# PIC32CZ4010CA90144 device description
Architecture: CORTEX-M7; Family: PIC32C; Series: PIC32CZCA90
Registers are 32-bit, read-write, reset 0x0 unless marked. A register's access mark holds for its fields unless they carry their own. Offsets are from the block's base; [hi:lo] are bit positions; {n}, {i} and the like mark numbered series; 'fields as' and 'values as' point back to an identical list; <NAME> marks a mode.

## HSM — Hardware Security Module
Instances: HSM 0x4F018000
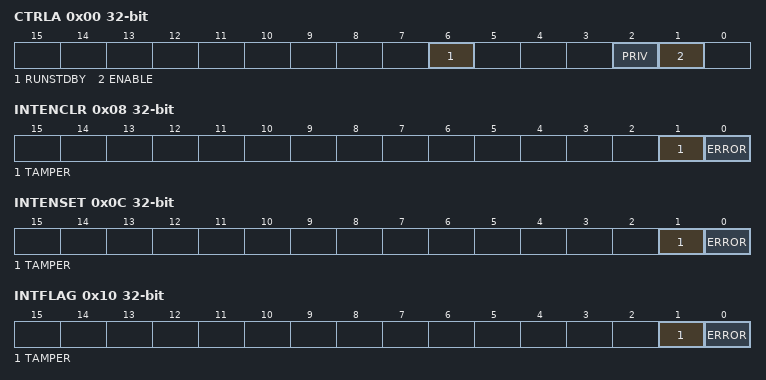
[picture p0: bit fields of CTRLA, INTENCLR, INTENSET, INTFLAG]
0x00 CTRLA — CONTROL REGISTER A
  [6] RUNSTDBY — Run In Standby bit
  [2] PRIV — Privileged Access Only bit
  [1] ENABLE — Clock Enable bit
0x04 CTRLB — CONTROL REGISTER B
  [0] CANCEL — Cancel Command
0x08 INTENCLR (atomic clear) — INTERRUPT ENABLE CLEAR REGISTER
  [1] TAMPER — Tamper Interrupt Enable
  [0] ERROR — Error Interrupt Enable
0x0C INTENSET (atomic set) — INTERRUPT ENABLE SET
  fields as INTENCLR
0x10 INTFLAG (atomic clear) — INTERRUPT FLAG
  [1] TAMPER — Tamper Interrupt Flag
  [0] ERROR — Error Interrupt Flag
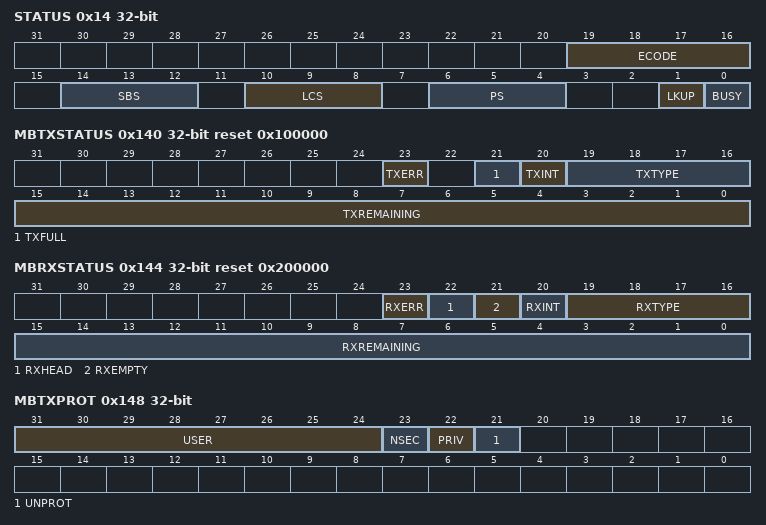
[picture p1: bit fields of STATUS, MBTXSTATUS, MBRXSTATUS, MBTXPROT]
0x14 STATUS
  [19:16] ECODE — ERROR CODE
  [14:12] SBS — SECURE BOOT STATE
  [10:8] LCS — LIFECYCLE STATE
  [6:4] PS — PROCESSING STATE
  [1] LKUP — HSM CPU LOCKUP
  [0] BUSY — HSM CPU BUSY
{0x100+4i} MBFIFO[{i}] (i=0..15) — MAILBOX FIFO
0x140 MBTXSTATUS reset 0x100000 — MAILBOX TRANSMIT STATUS
  [23] TXERR — TRANSMIT ERROR
  [21] TXFULL — TRANSMIT FIFO FULL
  [20] TXINT — TRANSMIT FIFO INTERRUPT FLAG
  [19:16] TXTYPE — TRANSMIT MESSAGE HEADER TYPE
  [15:0] TXREMAINING — TRANSMIT BYTES REMAINING
0x144 MBRXSTATUS reset 0x200000 — MAILBOX RECEIVE STATUS
  [23] RXERR — RECEIVE ERROR
  [22] RXHEAD — Receive Header Next Word bit
  [21] RXEMPTY — RECEIVE FIFO FULL
  [20] RXINT — RECEIVE FIFO INTERRUPT FLAG
  [19:16] RXTYPE — RECEIVE MESSAGE HEADER TYPE
  [15:0] RXREMAINING — RECEIVE BYTES REMAINING
0x148 MBTXPROT — MAILBOX TX PROTECTION
  [31:24] USER — USER SIDEBAND
  [23] NSEC — MAILBOX MESSAGE NON-SECURE ACCESS
  [22] PRIV — MAILBOX MESSAGE PRIVILEDGED ACCESS
  [21] UNPROT — MAILBOX UNPROTECTED
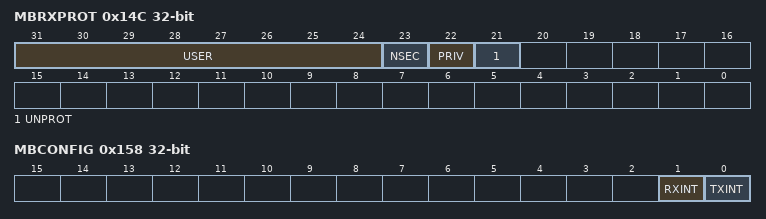
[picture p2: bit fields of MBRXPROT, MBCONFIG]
0x14C MBRXPROT — MAILBOX RX PROTECTION
  fields as MBTXPROT
0x150 MBTXHEAD — MAILBOX TRANSMIT HEADER
  [31:0] TXHEAD — MAILBOX TRANSMIT HEADER REGISTER
0x154 MBRXHEAD — MAILBOX RECEIVE HEADER
  [31:0] RXHEAD — MAILBOX RECEIVE HEADER REGISTER
0x158 MBCONFIG — MAILBOX CONFIGURATION
  [1] RXINT — MAILBOX RECEIVE INTERRUPT ENABLE
  [0] TXINT — MAILBOX TRANSMIT INTERRUPT ENABLE

## ITM — Instrumentation Trace Macrocell
Instances: ITM 0xE0041000
{0x0+4i} PORT[{i}] (i=0..31) wo reset not defined — ITM Stimulus Port Registers
  [7:0] PORT <BYTE>, [15:0] PORT <HWORD>, [31:0] PORT <WORD>
0xE00 TER reset not defined — ITM Trace Enable Register
0xE40 TPR reset not defined — ITM Trace Privilege Register
  [3:0] PRIVMASK
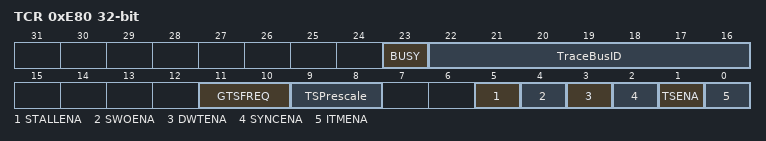
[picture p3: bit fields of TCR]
0xE80 TCR reset not defined — ITM Trace Control Register
  [23] BUSY, [22:16] TraceBusID, [11:10] GTSFREQ, [9:8] TSPrescale, [5] STALLENA, [4] SWOENA, [3] DWTENA, [2] SYNCENA, [1] TSENA, [0] ITMENA
0xEF8 IWR wo reset not defined — ITM Integration Write Register
  [0] ATVALIDM
0xEFC IRR ro reset not defined — ITM Integration Read Register
  [0] ATREADYM

## MCLK — Main Clock
Instances: MCLK 0x44052000
0x00 INTENCLR (atomic clear) — Interrupt Enable Clear
  [0] CKRDY — Clock Ready Interrupt Enable
0x04 INTENSET (atomic set) — Interrupt Enable Set
  [0] CKRDY — Clock Ready Interrupt Enable
0x08 INTFLAG reset 0x1 (atomic clear) — Interrupt Flag Status and Clear
  [0] CKRDY — Clock Ready
{0xC+4i} CLKDIV[{i}] (i=0..1) — Clock Divider Control
  [7:0] DIV — Clock Domain Division Factor
    1=Divide by 1; 2=Divide by 2; 4=Divide by 4; 8=Divide by 8; 16=Divide by 16; 32=Divide by 32; 64=Divide by 64; 128=Divide by 128
{0x3C+4i} CLKMSK[{i}] (i=0..8) — Peripheral Clock Enable Mask
  [31:0] MASK

## MCRAMC — Multi-Channel RAM Controller
Instances: MCRAMC 0x44822000
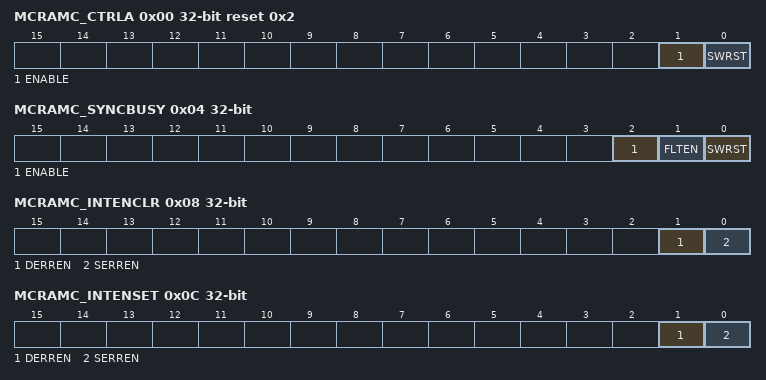
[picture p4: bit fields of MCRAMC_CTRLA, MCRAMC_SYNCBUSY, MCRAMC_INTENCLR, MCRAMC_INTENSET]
0x00 MCRAMC_CTRLA reset 0x2 — Control Enable A Register
  [1] ENABLE — ECC Decoder Enable
    0=ECC decoding is disabled; 1=ECC decoding is enabled
  [0] SWRST — Software Reset
    0=No effect; 1=Reset the MCRAMC. A software-triggered hardware reset of the MCRAMC user interface is performed.
0x04 MCRAMC_SYNCBUSY ro — Sync Busy Register
  [2] ENABLE — ECC Decoder Enable busy bit
  [1] FLTEN — Fault Injection Enabled busy bit
  [0] SWRST — Software reset busy bit
0x08 MCRAMC_INTENCLR (atomic clear) — Interrupt Enable Clear Register
  [1] DERREN — Double Bit Error Interrupt Enable, Clear
  [0] SERREN — Single Bit Error Interrupt Enable, Clear
0x0C MCRAMC_INTENSET (atomic set) — Interrupt Enable Set Register
  [1] DERREN — Double Bit Error Interrupt Enable, Set
  [0] SERREN — Single Bit Error Interrupt Enable, Set
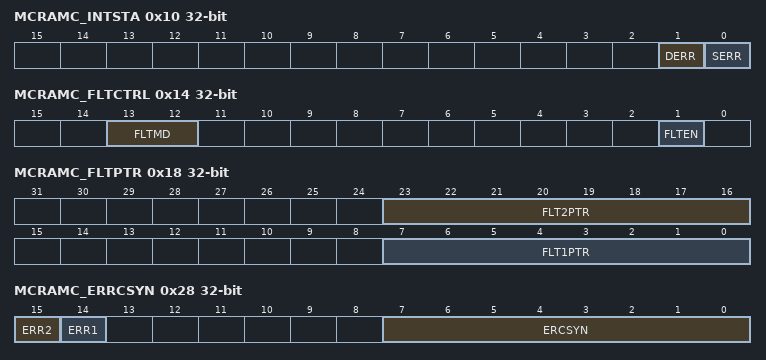
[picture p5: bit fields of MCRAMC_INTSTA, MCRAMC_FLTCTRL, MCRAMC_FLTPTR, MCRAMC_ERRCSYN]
0x10 MCRAMC_INTSTA (atomic clear) — Interrupt Status Register
  [1] DERR — Double Bit Error
  [0] SERR — Single Bit Error
0x14 MCRAMC_FLTCTRL — Fault Injection Control Register
  [13:12] FLTMD — Fault Injection Mode
  [1] FLTEN — Fault Injection Enabled
    0=Disables fault injection; 1=Enables fault injection at FLTADR address offset as selected by FLTMD and FLTxPTR
0x18 MCRAMC_FLTPTR — Fault Injection Pointer Register
  [23:16] FLT2PTR — Double Fault Injection Bit Pointer
  [7:0] FLT1PTR — Single Fault Injection Bit Pointer
0x1C MCRAMC_FLTADR — Fault Injection Address Register
  [23:0] FLTADR — Fault Address Offset
0x20 MCRAMC_ERRCADR ro — Error Capture Address Register
  [23:0] ERCADR — ECC SECDED Error Capture Address
0x24 MCRAMC_ERRCPAR ro — Error Capture Parity Register
  [7:0] ERCPAR — ECC SECDED Error Capture Parity
0x28 MCRAMC_ERRCSYN ro — Error Capture Syndrome Register
  [15] ERR2 — ECC Double Bit Error
    0=Not a Double bit error; 1=Double bit error
  [14] ERR1 — ECC Single Bit Error
  [7:0] ERCSYN — ECC SECDED Error Capture Syndrome
    0=Not a Single bit error; 1=Single bit error
